# RSL15 register map
Vendor: ONSemiconductor; Series: RSL15 Series; File version: 1.0
CPU: CM33 r0p4, little endian, MPU, FPU, 3 interrupt priority bits
Registers are 32-bit, read-write, reset 0x0 unless marked. A register's access mark holds for its fields unless they carry their own. Offsets are from the block's base; [hi:lo] are bit positions; {n}, {i} and the like mark numbered series.

## ASCC
Base 0x40001700
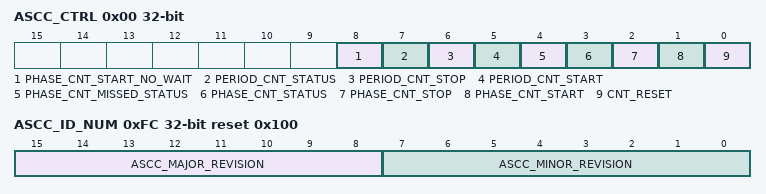
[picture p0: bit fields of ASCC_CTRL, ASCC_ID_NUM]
0x00 ASCC_CTRL (reset mask 0x98) — ASCC Control Register
  [8] PHASE_CNT_START_NO_WAIT wo — Start the asynchronous clock phase counter mechanism without waiting on a sync pulse
    1=PHASE_CNT_START_NO_WAIT (Reset PHASE_CNT and start the asynchronous clock phase counter mechanism without waiting on a sync pulse)
  [7] PERIOD_CNT_STATUS ro — Asynchronous clock period counter status
    0=PERIOD_CNT_IDLE (The asynchronous clock period counter mechanism is idle); 1=PERIOD_CNT_BUSY (The asynchronous clock period counter mechanism is busy)
  [6] PERIOD_CNT_STOP wo — Stop the asynchronous clock period counter mechanism
    1=PERIOD_CNT_STOP (Stop the asynchronous clock period counter mechanism)
  [5] PERIOD_CNT_START wo — Start the asynchronous clock period counter mechanism
    1=PERIOD_CNT_START (Reset PERIOD_CNT and start the asynchronous clock period counter mechanism)
  [4] PHASE_CNT_MISSED_STATUS ro — Asynchronous clock phase counter missed status
    0=PHASE_CNT_NORMAL (The asynchronous clock phase counter mechanism was not stopped due to a missed synchronization signal); 1=PHASE_CNT_MISSED (The asynchronous clock phase counter mechanism was stopped due to a missed synchronization signal)
  [3] PHASE_CNT_STATUS ro — Asynchronous clock phase counter status
    0=PHASE_CNT_IDLE (The asynchronous clock phase counter mechanism is idle); 1=PHASE_CNT_BUSY (The asynchronous clock phase counter mechanism is busy)
  [2] PHASE_CNT_STOP wo — Stop the asynchronous clock phase counter mechanism
    1=PHASE_CNT_STOP (Stop the asynchronous clock phase counter mechanism)
  [1] PHASE_CNT_START wo — Start the asynchronous clock phase counter mechanism and wait for sync pulse
    1=PHASE_CNT_START (Reset PHASE_CNT and start the asynchronous clock phase counter mechanism and wait on a sync pulse)
  [0] CNT_RESET wo — Reset asynchronous clock counter
    1=CNT_RESET (Reset asynchronous clock counter)
0x04 ASCC_CFG — ASCC Configuration Register
  [3:0] PERIODS_CFG — Defines over how many asynchronous clock periods the period counter measures
    0=ASCC_PERIODS_1 (Measure 1 asynchronous clock period); {v}=ASCC_PERIODS_{v+1} (Measure {v+1} asynchronous clock periods) (v=1..15)
0x08 ASCC_CNT ro — ASCC Counter Register
  [11:0] CNT — Asynchronous clock counter value
0x0C ASCC_PHASE_CNT — ASCC Phase Counter Register
  [15:0] PHASE_CNT — Asynchronous clock phase counter value
0x10 ASCC_PERIOD_CNT — ASCC Period Counter Register
  [15:0] PERIOD_CNT — Asynchronous clock period counter value
0xFC ASCC_ID_NUM ro reset 0x100 — ASCC ID number
  [15:8] ASCC_MAJOR_REVISION — ASCC Major Revision number
    1=ASCC_MAJOR_REVISION (ASCC revision 1.0)
  [7:0] ASCC_MINOR_REVISION — ASCC Minor Revision number
    0=ASCC_MINOR_REVISION (ASCC revision 1.0)

## ICB — Implementation Control Block
Base 0xE000E004
0x00 ICB_ICTR ro reset 0x1 — Interrupt Controller Type Register
  [3:0] INTLINESNUM — Number of interrupt inputs in steps of 32
    1=NVIC_INTLINESNUM_33_64

## SysTick — SysTick Timer
Base 0xE000E010
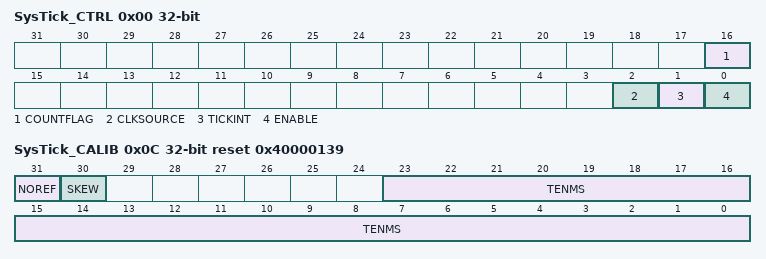
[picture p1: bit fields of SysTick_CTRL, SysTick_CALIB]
0x00 SysTick_CTRL — SysTick Control and Status Register
  [16] COUNTFLAG ro — Reads as 1 if SYSTICK counter has reached 0 since the last time the timer has reached 0. Clears to 0 on read.
    0=SYSTICK_COUNTFLAG_NOT_ZERO (SYSTICK counter has not reached zero since last read); 1=SYSTICK_COUNTFLAG_ZERO (SYSTICK counter has reached zero since last read)
  [2] CLKSOURCE — SYSTICK timer clock source
    0=SYSTICK_CLKSOURCE_EXTREF_CLK (Use external reference clock (STCLK)); 1=SYSTICK_CLKSOURCE_CORE_CLK (Use the core clock)
  [1] TICKINT — SYSTICK timer interrupt enable
    0=SYSTICK_TICKINT_DISABLE (Disable interrupt generation when SYSTICK timer reaches 0); 1=SYSTICK_TICKINT_ENABLE (Enable interrupt generation when SYSTICK timer reaches 0)
  [0] ENABLE — SYSTICK timer enable
    0=SYSTICK_DISABLE (Disable SYSTICK timer); 1=SYSTICK_ENABLE (Enable SYSTICK Timer)
0x04 SysTick_LOAD — SysTick Reload Value Register
  [23:0] RELOAD — Counter reload value for the SYSTICK timer when it reaches 0
0x08 SysTick_VAL — SysTick Current Value Register
  [23:0] CURRENT — Current value of the SYSTICK counter value. Write to clear counter.
0x0C SysTick_CALIB ro reset 0x40000139 — SysTick Calibration Register
  [31] NOREF — Indicates if a reference clock is available
    1=SYSTICK_NOREF (No external reference clock available); 0=SYSTICK_REF (External reference clock available)
  [30] SKEW — Indicates if calibration value is exactly 10 ms or not
    1=SYSTICK_SKEW (Calibration value is not exactly 10 ms); 0=SYSTICK_NOSKEW (Calibration value is exactly 10 ms)
  [23:0] TENMS — SYSTICK counter calibration value for 10 ms. A value of 0 means the calibration value is not available
